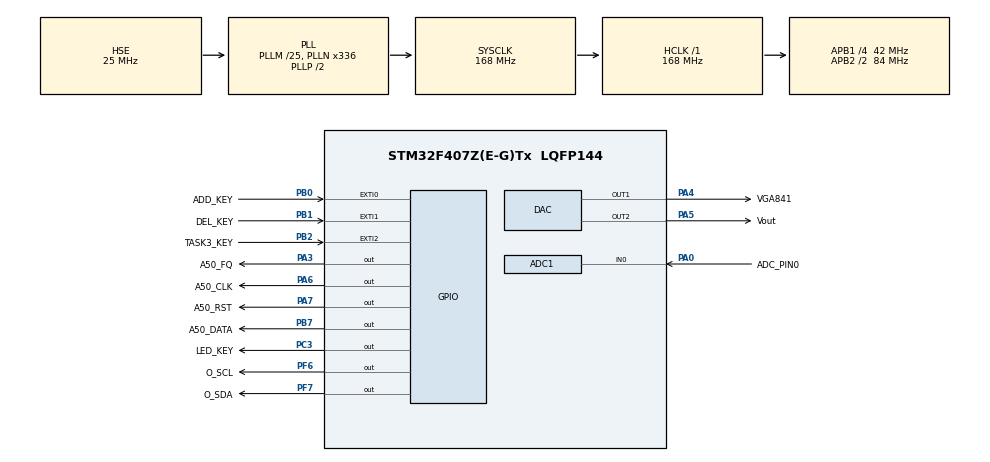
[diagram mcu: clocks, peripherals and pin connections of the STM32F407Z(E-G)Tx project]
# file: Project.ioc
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ADC1.Channel-2\#ChannelRegularConversion=ADC_CHANNEL_0
ADC1.DMAContinuousRequests=ENABLE
ADC1.ExternalTrigConv=ADC_EXTERNALTRIGCONV_T3_TRGO
ADC1.NbrOfConversion=1
ADC1.NbrOfConversionFlag=1
ADC1.Rank-2\#ChannelRegularConversion=1
ADC1.SamplingTime-2\#ChannelRegularConversion=ADC_SAMPLETIME_3CYCLES
ADC1.master=1
DAC.DAC_Trigger2=DAC_TRIGGER_T6_TRGO
Dma.ADC1.1.Direction=DMA_PERIPH_TO_MEMORY
Dma.ADC1.1.FIFOMode=DMA_FIFOMODE_DISABLE
Dma.ADC1.1.Instance=DMA2_Stream0
Dma.ADC1.1.MemDataAlignment=DMA_MDATAALIGN_HALFWORD
Dma.ADC1.1.MemInc=DMA_MINC_ENABLE
Dma.ADC1.1.Mode=DMA_CIRCULAR
Dma.ADC1.1.PeriphDataAlignment=DMA_PDATAALIGN_HALFWORD
Dma.ADC1.1.PeriphInc=DMA_PINC_DISABLE
Dma.ADC1.1.Priority=DMA_PRIORITY_HIGH
Dma.DAC2.0.Direction=DMA_MEMORY_TO_PERIPH
Dma.DAC2.0.FIFOMode=DMA_FIFOMODE_DISABLE
Dma.DAC2.0.Instance=DMA1_Stream6
Dma.DAC2.0.MemDataAlignment=DMA_MDATAALIGN_HALFWORD
Dma.DAC2.0.MemInc=DMA_MINC_ENABLE
Dma.DAC2.0.Mode=DMA_CIRCULAR
Dma.DAC2.0.PeriphDataAlignment=DMA_PDATAALIGN_HALFWORD
Dma.DAC2.0.PeriphInc=DMA_PINC_DISABLE
Dma.DAC2.0.Priority=DMA_PRIORITY_HIGH
Dma.Request0=DAC2
Dma.Request1=ADC1
Mcu.Family=STM32F4
Mcu.Name=STM32F407Z(E-G)Tx
Mcu.Package=LQFP144
NVIC.DMA1_Stream6_IRQn=true\:0\:0\:true\:false\:true\:false\:true\:true
NVIC.DMA2_Stream0_IRQn=true\:0\:0\:true\:false\:true\:false\:true\:true
NVIC.EXTI0_IRQn=true\:5\:0\:true\:false\:true\:true\:true\:true
NVIC.EXTI1_IRQn=true\:5\:0\:true\:false\:true\:true\:true\:true
NVIC.EXTI2_IRQn=true\:5\:0\:true\:false\:true\:true\:true\:true
NVIC.PriorityGroup=NVIC_PRIORITYGROUP_4
PA0-WKUP.GPIO_Label=ADC_PIN0
PA0-WKUP.Signal=ADCx_IN0
PA13.Mode=Serial_Wire
PA13.Signal=SYS_JTMS-SWDIO
PA14.Mode=Serial_Wire
PA14.Signal=SYS_JTCK-SWCLK
PA3.GPIO_Label=A50_FQ
PA3.GPIO_ModeDefaultOutputPP=GPIO_MODE_OUTPUT_PP
PA3.GPIO_Speed=GPIO_SPEED_FREQ_HIGH
PA3.Signal=GPIO_Output
PA4.GPIO_Label=VGA841
PA4.Signal=COMP_DAC1_group
PA5.GPIO_Label=Vout
PA5.Signal=COMP_DAC2_group
PA6.GPIO_Label=A50_CLK
PA6.GPIO_Speed=GPIO_SPEED_FREQ_HIGH
PA6.Signal=GPIO_Output
PA7.GPIO_Label=A50_RST
PA7.GPIO_Speed=GPIO_SPEED_FREQ_HIGH
PA7.Signal=GPIO_Output
PB0.GPIO_Label=ADD_KEY
PB0.GPIO_ModeDefaultEXTI=GPIO_MODE_IT_FALLING
PB0.GPIO_PuPd=GPIO_PULLUP
PB0.Signal=GPXTI0
PB1.GPIO_Label=DEL_KEY
PB1.GPIO_ModeDefaultEXTI=GPIO_MODE_IT_FALLING
PB1.GPIO_PuPd=GPIO_PULLUP
PB1.Signal=GPXTI1
PB2.GPIO_Label=TASK3_KEY
PB2.GPIO_ModeDefaultEXTI=GPIO_MODE_IT_FALLING
PB2.GPIO_PuPd=GPIO_PULLUP
PB2.Signal=GPXTI2
PB7.GPIO_Label=A50_DATA
PB7.GPIO_Speed=GPIO_SPEED_FREQ_HIGH
PB7.Signal=GPIO_Output
PC14-OSC32_IN.Mode=LSE-External-Oscillator
PC14-OSC32_IN.Signal=RCC_OSC32_IN
PC15-OSC32_OUT.Mode=LSE-External-Oscillator
PC15-OSC32_OUT.Signal=RCC_OSC32_OUT
PC3.GPIO_Label=LED_KEY
PC3.PinState=GPIO_PIN_SET
PC3.Signal=GPIO_Output
PF6.GPIO_Label=O_SCL
PF6.GPIO_ModeDefaultOutputPP=GPIO_MODE_OUTPUT_OD
PF6.GPIO_PuPd=GPIO_PULLUP
PF6.GPIO_Speed=GPIO_SPEED_FREQ_HIGH
PF6.PinState=GPIO_PIN_SET
PF6.Signal=GPIO_Output
PF7.GPIO_Label=O_SDA
PF7.GPIO_ModeDefaultOutputPP=GPIO_MODE_OUTPUT_OD
PF7.GPIO_PuPd=GPIO_PULLUP
PF7.GPIO_Speed=GPIO_SPEED_FREQ_HIGH
PF7.PinState=GPIO_PIN_SET
PF7.Signal=GPIO_Output
PH0-OSC_IN.Mode=HSE-External-Oscillator
PH0-OSC_IN.Signal=RCC_OSC_IN
PH1-OSC_OUT.Mode=HSE-External-Oscillator
PH1-OSC_OUT.Signal=RCC_OSC_OUT
ProjectManager.HeapSize=0x200
ProjectManager.StackSize=0x2000
ProjectManager.TargetToolchain=MDK-ARM V5.32
RCC.48MHZClocksFreq_Value=84000000
RCC.AHBFreq_Value=168000000
RCC.APB1CLKDivider=RCC_HCLK_DIV4
RCC.APB1Freq_Value=42000000
RCC.APB1TimFreq_Value=84000000
RCC.APB2CLKDivider=RCC_HCLK_DIV2
RCC.APB2Freq_Value=84000000
RCC.APB2TimFreq_Value=168000000
RCC.CortexFreq_Value=168000000
RCC.HCLKFreq_Value=168000000
RCC.HSE_VALUE=25000000
RCC.HSI_VALUE=16000000
RCC.PLLM=25
RCC.PLLN=336
RCC.PLLSourceVirtual=RCC_PLLSOURCE_HSE
RCC.SYSCLKFreq_VALUE=168000000
RCC.SYSCLKSource=RCC_SYSCLKSOURCE_PLLCLK
RCC.VCOOutputFreq_Value=336000000
SH.ADCx_IN0.0=ADC1_IN0,IN0
SH.COMP_DAC1_group.0=DAC_OUT1,DAC_OUT1
SH.COMP_DAC2_group.0=DAC_OUT2,DAC_OUT2
TIM3.AutoReloadPreload=TIM_AUTORELOAD_PRELOAD_ENABLE
TIM3.Period=105-1
TIM3.Prescaler=1-1
TIM3.TIM_MasterOutputTrigger=TIM_TRGO_UPDATE
TIM6.AutoReloadPreload=TIM_AUTORELOAD_PRELOAD_ENABLE
TIM6.Period=336-1
TIM6.Prescaler=1-1
TIM6.TIM_MasterOutputTrigger=TIM_TRGO_UPDATE
VP_TIM3_VS_ClockSourceINT.Mode=Internal
VP_TIM6_VS_ClockSourceINT.Mode=Enable_Timer
board=custom

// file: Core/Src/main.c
/* USER CODE BEGIN Header */
/**
  ******************************************************************************
  * @file           : main.c
  * @brief          : Main program body
  ******************************************************************************
  * @attention
  *
  * Copyright (c) 2026 STMicroelectronics.
  * All rights reserved.
  *
  * This software is licensed under terms that can be found in the LICENSE file
  * in the root directory of this software component.
  * If no LICENSE file comes with this software, it is provided AS-IS.
  *
  ******************************************************************************
  */
/* USER CODE END Header */
#include "main.h"
#include "adc.h"
#include "dac.h"
#include "dma.h"
#include "tim.h"
#include "gpio.h"

/* USER CODE BEGIN Includes */
#include "app_main.h"
#include "test.h"
/* USER CODE END Includes */

/* USER CODE BEGIN PTD */
static void config_test_loop(void) {
    // 编码对齐测试：如果你看到的是正常汉字，说明设置正确；如果是乱码，请修改 Encoding 为 GB2312
    //点灯测试，我板子的调试小灯对应PC3，可根据需求自行更改，确保正确移植，测试后可删除
    HAL_GPIO_TogglePin(GPIOC, GPIO_PIN_3);
    HAL_Delay(5000);
}
/* USER CODE END PTD */

void SystemClock_Config(void);

int main(void)
{

  /* MCU Configuration--------------------------------------------------------*/

  /* Reset of all peripherals, Initializes the Flash interface and the Systick. */
  HAL_Init();

  /* Configure the system clock */
  SystemClock_Config();

  /* Initialize all configured peripherals */
  MX_GPIO_Init();
  MX_DMA_Init();
  MX_DAC_Init();
  MX_TIM6_Init();
  MX_ADC1_Init();
  MX_TIM3_Init();
  /* USER CODE BEGIN 2 */

  app_init();
  /* USER CODE END 2 */

  /* Infinite loop */
  while (1)
  {

    /* USER CODE BEGIN 3 */
    app_loop();
    // 开环测试，空循环即可
  }
  /* USER CODE END 3 */
}

void SystemClock_Config(void)
{
  RCC_OscInitTypeDef RCC_OscInitStruct = {0};
  RCC_ClkInitTypeDef RCC_ClkInitStruct = {0};

  /** Configure the main internal regulator output voltage
  */
  __HAL_RCC_PWR_CLK_ENABLE();
  __HAL_PWR_VOLTAGESCALING_CONFIG(PWR_REGULATOR_VOLTAGE_SCALE1);

  /** Initializes the RCC Oscillators according to the specified parameters
  * in the RCC_OscInitTypeDef structure.
  */
  RCC_OscInitStruct.OscillatorType = RCC_OSCILLATORTYPE_HSE;
  RCC_OscInitStruct.HSEState = RCC_HSE_ON;
  RCC_OscInitStruct.PLL.PLLState = RCC_PLL_ON;
  RCC_OscInitStruct.PLL.PLLSource = RCC_PLLSOURCE_HSE;
  RCC_OscInitStruct.PLL.PLLM = 25;
  RCC_OscInitStruct.PLL.PLLN = 336;
  RCC_OscInitStruct.PLL.PLLP = RCC_PLLP_DIV2;
  RCC_OscInitStruct.PLL.PLLQ = 4;
  if (HAL_RCC_OscConfig(&RCC_OscInitStruct) != HAL_OK)
  {
    Error_Handler();
  }

  /** Initializes the CPU, AHB and APB buses clocks
  */
  RCC_ClkInitStruct.ClockType = RCC_CLOCKTYPE_HCLK|RCC_CLOCKTYPE_SYSCLK
                              |RCC_CLOCKTYPE_PCLK1|RCC_CLOCKTYPE_PCLK2;
  RCC_ClkInitStruct.SYSCLKSource = RCC_SYSCLKSOURCE_PLLCLK;
  RCC_ClkInitStruct.AHBCLKDivider = RCC_SYSCLK_DIV1;
  RCC_ClkInitStruct.APB1CLKDivider = RCC_HCLK_DIV4;
  RCC_ClkInitStruct.APB2CLKDivider = RCC_HCLK_DIV2;

  if (HAL_RCC_ClockConfig(&RCC_ClkInitStruct, FLASH_LATENCY_5) != HAL_OK)
  {
    Error_Handler();
  }
}

void Error_Handler(void)
{
  __disable_irq();
  while (1)
  {
  }
}
